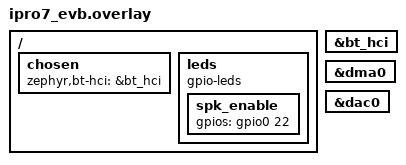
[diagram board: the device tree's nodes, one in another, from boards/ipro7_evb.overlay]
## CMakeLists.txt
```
# Copyright (c) 2026 INTELPRO
# SPDX-License-Identifier: Apache-2.0
#
# LE Audio unicast headset on the IPRO7AI EVK: CAP acceptor (CAS + CSIP set
# member), PACS/ASCS sink, VCP volume renderer; a phone's LE Audio unicast
# client (Android "LE Audio" headphones) streams LC3 over a CIS, decoded and
# played on the GPDAC speaker. Port of apps/bluetooth/le_audio/ipro_le_audio_headset.
cmake_minimum_required(VERSION 3.20.0)
find_package(Zephyr REQUIRED HINTS $ENV{ZEPHYR_BASE})
project(le_audio_headset_ipro)

target_include_directories(app PRIVATE ../common/audio)
target_sources(app PRIVATE src/main.c src/bap_server.c src/audio.c ../common/audio/pcm_out.c)
```

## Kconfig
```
# Copyright (c) 2026 INTELPRO
# SPDX-License-Identifier: Apache-2.0

mainmenu "Bluetooth: LE Audio unicast headset (IPRO7)"

config HEADSET_DEVICE_NAME
	string "Advertised device name"
	default "IPRO-LE-Audio"

config HEADSET_SINK_LOCATION
	int "PACS sink audio location bitmask (1 = front left, 2 = front right)"
	default 1

source "Kconfig.zephyr"
```

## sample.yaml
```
sample:
  name: LE Audio unicast headset (CAP acceptor, LC3 -> GPDAC speaker) on the IPRO7AI EVK
tests:
  sample.ipro.le_audio_headset:
    platform_allow:
      - ipro7ai_evk
    integration_platforms:
      - ipro7ai_evk
    tags:
      - ipro
      - bluetooth
      - leaudio
    build_only: true
```

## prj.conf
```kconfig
CONFIG_BT=y
CONFIG_LOG=y
CONFIG_LOG_MODE_MINIMAL=y
CONFIG_UTF8=y
CONFIG_BT_PERIPHERAL=y
CONFIG_BT_DEVICE_NAME="IPRO-LE-Audio"
CONFIG_BT_DEVICE_APPEARANCE=1089
CONFIG_BT_GAP_AUTO_UPDATE_CONN_PARAMS=n
CONFIG_BT_PERIPHERAL_PREF_MIN_INT=50
CONFIG_BT_PERIPHERAL_PREF_MAX_INT=70
CONFIG_BT_PERIPHERAL_PREF_LATENCY=0
CONFIG_BT_PERIPHERAL_PREF_TIMEOUT=400
CONFIG_BT_GATT_DYNAMIC_DB=y
CONFIG_BT_GATT_CLIENT=y
CONFIG_BT_SMP=y
CONFIG_BT_BONDABLE=y
CONFIG_BT_PRIVACY=y
CONFIG_BT_KEYS_OVERWRITE_OLDEST=y
CONFIG_BT_MAX_PAIRED=4
CONFIG_BT_SETTINGS=y
CONFIG_SETTINGS=y
CONFIG_SETTINGS_NVS=y
CONFIG_NVS=y
CONFIG_FLASH=y
CONFIG_FLASH_MAP=y
CONFIG_FLASH_PAGE_LAYOUT=y

# LE Audio: CAP acceptor, BAP unicast server (sink), VCP renderer
CONFIG_BT_AUDIO=y
CONFIG_BT_CAP_ACCEPTOR=y
CONFIG_BT_CAP_ACCEPTOR_SET_MEMBER=y
CONFIG_BT_CSIP_SET_MEMBER=y
CONFIG_BT_BAP_UNICAST_SERVER=y
CONFIG_BT_ATT_PREPARE_COUNT=1
CONFIG_BT_ASCS=y
CONFIG_BT_ASCS_MAX_ASE_SNK_COUNT=2
CONFIG_BT_ASCS_MAX_ASE_SRC_COUNT=0
CONFIG_BT_PAC_SNK=y
CONFIG_BT_PAC_SNK_LOC=y
CONFIG_BT_VCP_VOL_REND=y
CONFIG_BT_AUDIO_CODEC_CFG_MAX_METADATA_SIZE=24
CONFIG_BT_ISO_PERIPHERAL=y
CONFIG_BT_ISO_MAX_CHAN=2
CONFIG_BT_ISO_RX_BUF_COUNT=8
CONFIG_BT_ISO_RX_MTU=251
CONFIG_BT_BUF_ACL_RX_SIZE=255
CONFIG_BT_BUF_ACL_TX_SIZE=251
CONFIG_BT_L2CAP_TX_MTU=247

# LC3 decode (liblc3, FPU)
CONFIG_LIBLC3=y
CONFIG_FPU=y
CONFIG_MAIN_STACK_SIZE=8192
CONFIG_BT_RX_STACK_SIZE=4096
CONFIG_COMMON_LIBC_MALLOC_ARENA_SIZE=8192

# IPRO7 controller: CIS peripheral needs the ISO archive and 32 KB EM
CONFIG_IPRO7_EM_SIZE_KB=32
CONFIG_BT_IPRO_CTLR_LIB="link1_periph"
CONFIG_BT_IPRO_CTLR_FEATURE="bt54_iso2"
CONFIG_BT_MAX_CONN=1
CONFIG_ENTROPY_GENERATOR=y

# Speaker
CONFIG_DMA=y
CONFIG_DAC=y
CONFIG_DAC_IPRO_STREAM=y
CONFIG_GPIO=y
```

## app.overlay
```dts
/ {
	chosen {
		zephyr,bt-hci = &bt_hci;
	};
};

&bt_hci {
	status = "okay";
};

&dma0 {
	status = "okay";
};

&dac0 {
	status = "okay";
};
```

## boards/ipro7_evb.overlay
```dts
/ {
	chosen {
		zephyr,bt-hci = &bt_hci;
	};
};

&bt_hci {
	status = "okay";
};

&dma0 {
	status = "okay";
};

&dac0 {
	status = "okay";
};
/* Bench smoke on the EVB (no speaker): a spare pad stands in for the
 * class-D enable so the sample builds and the BLE side can be exercised. */
/ {
	leds {
		compatible = "gpio-leds";
		spk_enable: spk_enable {
			gpios = <&gpio0 22 GPIO_ACTIVE_HIGH>;
		};
	};
};
```

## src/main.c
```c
/*
 * Copyright (c) 2026 INTELPRO
 * SPDX-License-Identifier: Apache-2.0
 *
 * LE Audio unicast headset: advertises as a CAP acceptor (CAS + CSIP set
 * member of size 1, ASCS unicast announcement, Earbud appearance, RSI), lets
 * a phone connect, pair (bond kept in NVS) and stream LC3 to the speaker;
 * VCP volume renderer drives the output gain.
 */
#include <zephyr/kernel.h>
#include <zephyr/bluetooth/bluetooth.h>
#include <zephyr/bluetooth/conn.h>
#include <zephyr/bluetooth/gap.h>
#include <zephyr/bluetooth/uuid.h>
#include <zephyr/bluetooth/audio/audio.h>
#include <zephyr/bluetooth/audio/cap.h>
#include <zephyr/bluetooth/audio/csip.h>
#include <zephyr/bluetooth/audio/vcp.h>
#include <zephyr/settings/settings.h>
#include <zephyr/logging/log.h>
#include "audio.h"
#include "pcm_out.h"

LOG_MODULE_REGISTER(headset, CONFIG_LOG_DEFAULT_LEVEL);

int bap_server_init(void);

#define DEVICE_NAME     CONFIG_HEADSET_DEVICE_NAME
#define DEVICE_NAME_LEN (sizeof(DEVICE_NAME) - 1)

static const struct bt_data ad[] = {
	BT_DATA_BYTES(BT_DATA_FLAGS, (BT_LE_AD_GENERAL | BT_LE_AD_NO_BREDR)),
	BT_DATA(BT_DATA_NAME_COMPLETE, DEVICE_NAME, DEVICE_NAME_LEN),
	/* ASCS unicast announcement: general, no metadata */
	BT_DATA_BYTES(BT_DATA_SVC_DATA16, BT_UUID_16_ENCODE(BT_UUID_ASCS_VAL),
		      BT_AUDIO_UNICAST_ANNOUNCEMENT_GENERAL, 0x00),
};

/* Scan response: appearance, service list, and the CSIS RSI added at start. */
static const struct bt_data sd_static[] = {
	BT_DATA_BYTES(BT_DATA_GAP_APPEARANCE, BT_BYTES_LIST_LE16(CONFIG_BT_DEVICE_APPEARANCE)),
	BT_DATA_BYTES(BT_DATA_UUID16_ALL, BT_UUID_16_ENCODE(BT_UUID_CAS_VAL),
		      BT_UUID_16_ENCODE(BT_UUID_ASCS_VAL), BT_UUID_16_ENCODE(BT_UUID_PACS_VAL),
		      BT_UUID_16_ENCODE(BT_UUID_VCS_VAL)),
};

static struct bt_csip_set_member_svc_inst *csip_inst;
static uint8_t rsi[BT_CSIP_RSI_SIZE];
static struct bt_conn *current_conn;
static struct k_work_delayable adv_work;

static int advertising_start(void)
{
	struct bt_data sd[ARRAY_SIZE(sd_static) + 1];
	size_t sd_len = 0;
	int err;

	if (current_conn != NULL) {
		return 0;
	}
	for (size_t i = 0; i < ARRAY_SIZE(sd_static); i++) {
		sd[sd_len++] = sd_static[i];
	}
	if (csip_inst != NULL && bt_csip_set_member_generate_rsi(csip_inst, rsi) == 0) {
		sd[sd_len++] = (struct bt_data)BT_DATA(BT_DATA_CSIS_RSI, rsi, sizeof(rsi));
	}
	err = bt_le_adv_start(BT_LE_ADV_CONN_FAST_2, ad, ARRAY_SIZE(ad), sd, sd_len);
	if (err != 0 && err != -EALREADY) {
		LOG_ERR("advertising start: %d", err);
		return err;
	}
	LOG_INF("advertising as \"%s\"", DEVICE_NAME);
	return 0;
}

static void adv_work_fn(struct k_work *work)
{
	ARG_UNUSED(work);
	(void)advertising_start();
}

static void connected(struct bt_conn *conn, uint8_t err)
{
	char addr[BT_ADDR_LE_STR_LEN];

	bt_addr_le_to_str(bt_conn_get_dst(conn), addr, sizeof(addr));
	if (err != 0) {
		LOG_ERR("connection to %s failed (0x%02x)", addr, err);
		(void)k_work_reschedule(&adv_work, K_MSEC(500));
		return;
	}
	if (current_conn != NULL) {
		(void)bt_conn_disconnect(conn, BT_HCI_ERR_REMOTE_USER_TERM_CONN);
		return;
	}
	current_conn = bt_conn_ref(conn);
	LOG_INF("connected: %s", addr);
	err = bt_conn_set_security(conn, BT_SECURITY_L2);
	if (err != 0) {
		LOG_WRN("set security: %d", err);
	}
}

static void disconnected(struct bt_conn *conn, uint8_t reason)
{
	LOG_INF("disconnected (0x%02x)", reason);
	audio_stop();
	if (current_conn == conn) {
		bt_conn_unref(current_conn);
		current_conn = NULL;
	}
	(void)k_work_reschedule(&adv_work, K_MSEC(500));
}

static void security_changed(struct bt_conn *conn, bt_security_t level, enum bt_security_err err)
{
	ARG_UNUSED(conn);
	LOG_INF("security level %d (err %d)", level, err);
}

BT_CONN_CB_DEFINE(conn_cbs) = {
	.connected = connected,
	.disconnected = disconnected,
	.security_changed = security_changed,
};

static void pairing_complete(struct bt_conn *conn, bool bonded)
{
	ARG_UNUSED(conn);
	LOG_INF("pairing complete, bonded %d", bonded);
}

static void pairing_failed(struct bt_conn *conn, enum bt_security_err reason)
{
	ARG_UNUSED(conn);
	LOG_WRN("pairing failed: %d (forget the device on the phone and retry)", reason);
}

static struct bt_conn_auth_info_cb auth_info_cbs = {
	.pairing_complete = pairing_complete,
	.pairing_failed = pairing_failed,
};

/* ---- VCP volume renderer ------------------------------------------------ */

static void vcp_state(struct bt_conn *conn, int err, uint8_t volume, uint8_t mute)
{
	ARG_UNUSED(conn);
	if (err != 0) {
		return;
	}
	LOG_INF("volume %u mute %u", volume, mute);
	audio_set_volume(volume, mute != 0);
}

static void vcp_flags(struct bt_conn *conn, int err, uint8_t flags)
{
	ARG_UNUSED(conn); ARG_UNUSED(err); ARG_UNUSED(flags);
}

static struct bt_vcp_vol_rend_cb vcp_cbs = {.state = vcp_state, .flags = vcp_flags};

static int vcp_init(void)
{
	struct bt_vcp_vol_rend_register_param param = {
		.step = 16, .mute = BT_VCP_STATE_UNMUTED, .volume = 200, .cb = &vcp_cbs,
	};
	int err = bt_vcp_vol_rend_register(&param);

	if (err == 0) {
		audio_set_volume(param.volume, false);
	}
	return err;
}

/* ---- CAP acceptor (CAS + CSIP set member) -------------------------------- */

static int cap_init(void)
{
	static const uint8_t sirk[BT_CSIP_SIRK_SIZE] = {0x12, 0x34, 0x56, 0x78, 0x9a, 0xbc,
							 0xde, 0xf0, 0x11, 0x22, 0x33, 0x44,
							 0x55, 0x66, 0x77, 0x88};
	struct bt_csip_set_member_register_param csip = {
		.set_size = 1, .rank = 1, .lockable = true,
	};

	memcpy(csip.sirk, sirk, sizeof(sirk));
	return bt_cap_acceptor_register(&csip, &csip_inst);
}

int main(void)
{
	int err;

	LOG_INF("LE Audio unicast headset (IPRO7AI EVK)");
	err = bt_enable(NULL);
	if (err != 0) {
		LOG_ERR("bt_enable: %d", err);
		return 0;
	}
	if (IS_ENABLED(CONFIG_BT_SETTINGS)) {
		err = settings_load();
		LOG_INF("settings load: %d", err);
	}
	(void)bt_conn_auth_info_cb_register(&auth_info_cbs);
	err = cap_init();
	LOG_INF("CAP acceptor: %d", err);
	err = bap_server_init();
	if (err != 0) {
		return 0;
	}
	err = vcp_init();
	LOG_INF("VCP renderer: %d", err);
	(void)pcm_out_init();
	k_work_init_delayable(&adv_work, adv_work_fn);
	(void)advertising_start();
	return 0;
}

#ifdef CONFIG_SHELL
#include <zephyr/shell/shell.h>

static int cmd_hs_unpair(const struct shell *sh, size_t argc, char **argv)
{
	ARG_UNUSED(argc); ARG_UNUSED(argv);
	int err = bt_unpair(BT_ID_DEFAULT, NULL);

	shell_print(sh, "unpair all: %d", err);
	return 0;
}

static int cmd_hs_disconnect(const struct shell *sh, size_t argc, char **argv)
{
	ARG_UNUSED(argc); ARG_UNUSED(argv);
	if (current_conn == NULL) {
		shell_print(sh, "not connected");
		return 0;
	}
	shell_print(sh, "disconnect: %d",
		    bt_conn_disconnect(current_conn, BT_HCI_ERR_REMOTE_USER_TERM_CONN));
	return 0;
}

SHELL_STATIC_SUBCMD_SET_CREATE(sub_hs,
	SHELL_CMD(unpair, NULL, "forget all bonds", cmd_hs_unpair),
	SHELL_CMD(disconnect, NULL, "drop the current link", cmd_hs_disconnect),
	SHELL_SUBCMD_SET_END);
SHELL_CMD_REGISTER(hs, &sub_hs, "LE Audio headset", NULL);
#endif
```

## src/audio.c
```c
/*
 * Copyright (c) 2026 INTELPRO
 * SPDX-License-Identifier: Apache-2.0
 *
 * LC3 decode for the headset: SDUs from the CIS are queued (net_buf ref) to
 * a decoder thread so the Bluetooth RX thread never waits on the codec;
 * decoded mono PCM goes to pcm_out (GPDAC speaker). A lost or errored SDU
 * replays the last good frame (halving per consecutive loss) rather than
 * liblc3's sign-randomising PLC, which is a burst of noise on music.
 */
#include <zephyr/kernel.h>
#include <zephyr/logging/log.h>
#include <lc3.h>
#include <string.h>
#include "audio.h"
#include "pcm_out.h"

LOG_MODULE_REGISTER(headset_audio, CONFIG_LOG_DEFAULT_LEVEL);

#define MAX_FRAME_SAMPLES 480 /* 48 kHz x 10 ms */
#define QUEUE_DEPTH 8

struct sdu {
	void *fifo_reserved;
	struct net_buf *buf;
	uint8_t flags;
};

K_MEM_SLAB_DEFINE_STATIC(sdu_slab, sizeof(struct sdu), QUEUE_DEPTH, 4);
static K_FIFO_DEFINE(sdu_fifo);
static K_THREAD_STACK_DEFINE(dec_stack, 8192);
static struct k_thread dec_thread;

static struct {
	uint32_t rate, dur_us;
	uint16_t octets;
	lc3_decoder_t dec;
	lc3_decoder_mem_48k_t mem;
	int16_t pcm[MAX_FRAME_SAMPLES];
	int16_t last_good[MAX_FRAME_SAMPLES];
	int frame_samples;
	uint8_t lost_run;
	bool streaming;
	uint32_t rx, decoded, concealed, dropped, errors;
} a;

static void decode_one(struct sdu *s)
{
	const bool valid = (s->flags & BT_ISO_FLAGS_VALID) != 0 && s->buf != NULL &&
			   s->buf->len == a.octets;

	if (a.dec == NULL) {
		return;
	}
	if (valid) {
		int r = lc3_decode(a.dec, s->buf->data, a.octets, LC3_PCM_FORMAT_S16, a.pcm, 1);

		if (r < 0) {
			a.errors++;
			return;
		}
		memcpy(a.last_good, a.pcm, a.frame_samples * sizeof(int16_t));
		a.lost_run = 0;
		a.decoded++;
	} else {
		const int shift = MIN(a.lost_run, 8);

		for (int i = 0; i < a.frame_samples; i++) {
			a.pcm[i] = (int16_t)(a.last_good[i] >> shift);
		}
		if (a.lost_run < UINT8_MAX) {
			a.lost_run++;
		}
		a.concealed++;
	}
	(void)pcm_out_write(a.pcm, a.frame_samples);
	if ((++a.rx % 1000) == 0) {
		struct pcm_out_stats st;

		pcm_out_stats(&st);
		LOG_INF("%u SDUs: decoded %u, concealed %u, errors %u, dropped %u | ring %u B, underruns %u, overruns %u, step %d, peak in %d out %d",
			a.rx, a.decoded, a.concealed, a.errors, a.dropped, st.ring_bytes,
			st.underruns, st.overruns, st.step_q16, st.in_peak, st.out_peak);
	}
}

static void dec_thread_fn(void *p1, void *p2, void *p3)
{
	ARG_UNUSED(p1); ARG_UNUSED(p2); ARG_UNUSED(p3);
	while (true) {
		struct sdu *s = k_fifo_get(&sdu_fifo, K_FOREVER);

		if (a.streaming) {
			decode_one(s);
		}
		if (s->buf != NULL) {
			net_buf_unref(s->buf);
		}
		k_mem_slab_free(&sdu_slab, (void *)s);
	}
}

int audio_configure(uint32_t sample_rate, uint32_t frame_dur_us, uint16_t octets_per_frame)
{
	static bool thread_started;

	if (!thread_started) {
		k_thread_create(&dec_thread, dec_stack, K_THREAD_STACK_SIZEOF(dec_stack),
				dec_thread_fn, NULL, NULL, NULL, K_PRIO_PREEMPT(5), 0, K_NO_WAIT);
		k_thread_name_set(&dec_thread, "lc3_dec");
		thread_started = true;
	}
	if (a.streaming && (sample_rate != a.rate || frame_dur_us != a.dur_us)) {
		audio_stop();
	}
	a.rate = sample_rate;
	a.dur_us = frame_dur_us;
	a.octets = octets_per_frame;
	a.frame_samples = lc3_frame_samples((int)frame_dur_us, (int)sample_rate);
	if (a.frame_samples <= 0 || a.frame_samples > MAX_FRAME_SAMPLES) {
		LOG_ERR("unsupported LC3 config %u Hz / %u us", sample_rate, frame_dur_us);
		a.dec = NULL;
		return -ENOTSUP;
	}
	a.dec = lc3_setup_decoder((int)frame_dur_us, (int)sample_rate, 0, &a.mem);
	if (a.dec == NULL) {
		LOG_ERR("lc3_setup_decoder failed");
		return -EINVAL;
	}
	memset(a.last_good, 0, sizeof(a.last_good));
	a.lost_run = 0;
	LOG_INF("LC3 %u Hz, %u us, %u octets/frame (%d samples)", sample_rate, frame_dur_us,
		octets_per_frame, a.frame_samples);
	return 0;
}

int audio_start(void)
{
	int r;

	if (a.dec == NULL) {
		return -EINVAL;
	}
	if (a.streaming) {
		return 0;
	}
	r = pcm_out_start(a.rate);
	if (r != 0) {
		LOG_ERR("pcm_out_start: %d", r);
		return r;
	}
	a.rx = 0; a.decoded = 0; a.concealed = 0; a.dropped = 0; a.errors = 0;
	a.streaming = true;
	return 0;
}

void audio_stop(void)
{
	a.streaming = false;
	pcm_out_stop();
}

void audio_push(const struct bt_iso_recv_info *info, struct net_buf *buf)
{
	struct sdu *s;

	if (!a.streaming) {
		return;
	}
	if (k_mem_slab_alloc(&sdu_slab, (void **)&s, K_NO_WAIT) != 0) {
		a.dropped++;
		return;
	}
	s->buf = net_buf_ref(buf);
	s->flags = info != NULL ? info->flags : 0;
	k_fifo_put(&sdu_fifo, s);
}

void audio_set_volume(uint8_t volume, bool mute)
{
	pcm_out_set_volume(volume, mute);
}
```

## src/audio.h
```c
/*
 * Copyright (c) 2026 INTELPRO
 * SPDX-License-Identifier: Apache-2.0
 */
#ifndef HEADSET_AUDIO_H
#define HEADSET_AUDIO_H

#include <stdint.h>
#include <stdbool.h>
#include <zephyr/net_buf.h>
#include <zephyr/bluetooth/iso.h>

/* Codec configuration negotiated on the sink ASE. */
int audio_configure(uint32_t sample_rate, uint32_t frame_dur_us, uint16_t octets_per_frame);
/* Streaming state: opens/closes the speaker path. */
int audio_start(void);
void audio_stop(void);
/* One SDU from the CIS (any context); decoded on the audio thread. */
void audio_push(const struct bt_iso_recv_info *info, struct net_buf *buf);
void audio_set_volume(uint8_t volume, bool mute);

#endif
```

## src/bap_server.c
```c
/*
 * Copyright (c) 2026 INTELPRO
 * SPDX-License-Identifier: Apache-2.0
 *
 * BAP unicast server (sink): PACS capability, ASCS callbacks, stream ops.
 * Codec capability as the FreeRTOS headset: LC3 16/32/48 kHz, 7.5/10 ms,
 * 1 channel, 26..155 octets (48_6 at 124 kbps is the top mono set); a phone
 * usually picks 48_2 or 48_4 for media, 32_2/16_2 for calls.
 */
#include <zephyr/kernel.h>
#include <zephyr/bluetooth/bluetooth.h>
#include <zephyr/bluetooth/conn.h>
#include <zephyr/bluetooth/audio/audio.h>
#include <zephyr/bluetooth/audio/bap.h>
#include <zephyr/bluetooth/audio/pacs.h>
#include <zephyr/bluetooth/audio/lc3.h>
#include <zephyr/logging/log.h>
#include "audio.h"

LOG_MODULE_REGISTER(bap_server, CONFIG_LOG_DEFAULT_LEVEL);

static const struct bt_audio_codec_cap lc3_sink_codec_cap = BT_AUDIO_CODEC_CAP_LC3(
	BT_AUDIO_CODEC_CAP_FREQ_16KHZ | BT_AUDIO_CODEC_CAP_FREQ_32KHZ |
		BT_AUDIO_CODEC_CAP_FREQ_48KHZ,
	BT_AUDIO_CODEC_CAP_DURATION_7_5 | BT_AUDIO_CODEC_CAP_DURATION_10 |
		BT_AUDIO_CODEC_CAP_DURATION_PREFER_10,
	BT_AUDIO_CODEC_CAP_CHAN_COUNT_SUPPORT(1), 26, 155, 1,
	BT_AUDIO_CONTEXT_TYPE_MEDIA | BT_AUDIO_CONTEXT_TYPE_CONVERSATIONAL);

static struct bt_pacs_cap lc3_sink_cap = {.codec_cap = &lc3_sink_codec_cap};

static struct bt_bap_stream streams[CONFIG_BT_ASCS_MAX_ASE_SNK_COUNT];
static bool stream_used[CONFIG_BT_ASCS_MAX_ASE_SNK_COUNT];
static struct bt_bap_stream_ops stream_ops;
static uint32_t rx_sdus, rx_lost;

static void fill_qos_pref(struct bt_bap_qos_cfg_pref *pref)
{
	pref->unframed_supported = true;
	pref->phy = BT_BAP_QOS_CFG_2M;
	pref->rtn = 2;
	pref->latency = 10;
	pref->pd_min = 10000;
	pref->pd_max = 40000;
	pref->pref_pd_min = 10000;
	pref->pref_pd_max = 20000;
}

static struct bt_bap_stream *stream_alloc(void)
{
	for (size_t i = 0; i < ARRAY_SIZE(streams); i++) {
		if (!stream_used[i]) {
			stream_used[i] = true;
			return &streams[i];
		}
	}
	return NULL;
}

static void stream_free(struct bt_bap_stream *stream)
{
	for (size_t i = 0; i < ARRAY_SIZE(streams); i++) {
		if (&streams[i] == stream) {
			stream_used[i] = false;
		}
	}
}

static int apply_codec_cfg(const struct bt_audio_codec_cfg *codec_cfg)
{
	int freq = bt_audio_codec_cfg_get_freq(codec_cfg);
	int dur = bt_audio_codec_cfg_get_frame_dur(codec_cfg);
	int octets = bt_audio_codec_cfg_get_octets_per_frame(codec_cfg);

	if (freq < 0 || dur < 0 || octets <= 0) {
		LOG_WRN("codec config incomplete (freq %d dur %d octets %d)", freq, dur, octets);
		return -EINVAL;
	}
	return audio_configure(bt_audio_codec_cfg_freq_to_freq_hz(freq),
			       bt_audio_codec_cfg_frame_dur_to_frame_dur_us(dur), (uint16_t)octets);
}

static int cb_config(struct bt_conn *conn, const struct bt_bap_ep *ep, enum bt_audio_dir dir,
		     const struct bt_audio_codec_cfg *codec_cfg, struct bt_bap_stream **stream,
		     struct bt_bap_qos_cfg_pref *const pref, struct bt_bap_ascs_rsp *rsp)
{
	ARG_UNUSED(conn); ARG_UNUSED(ep);
	if (dir != BT_AUDIO_DIR_SINK) {
		*rsp = BT_BAP_ASCS_RSP(BT_BAP_ASCS_RSP_CODE_CONF_UNSUPPORTED,
				       BT_BAP_ASCS_REASON_NONE);
		return -ENOTSUP;
	}
	*stream = stream_alloc();
	if (*stream == NULL) {
		*rsp = BT_BAP_ASCS_RSP(BT_BAP_ASCS_RSP_CODE_NO_MEM, BT_BAP_ASCS_REASON_NONE);
		return -ENOMEM;
	}
	bt_bap_stream_cb_register(*stream, &stream_ops);
	LOG_INF("ASE config: stream %p", (void *)*stream);
	if (codec_cfg != NULL && apply_codec_cfg(codec_cfg) != 0) {
		stream_free(*stream);
		*stream = NULL;
		*rsp = BT_BAP_ASCS_RSP(BT_BAP_ASCS_RSP_CODE_CONF_UNSUPPORTED,
				       BT_BAP_ASCS_REASON_CODEC_DATA);
		return -ENOTSUP;
	}
	fill_qos_pref(pref);
	*rsp = BT_BAP_ASCS_RSP(BT_BAP_ASCS_RSP_CODE_SUCCESS, BT_BAP_ASCS_REASON_NONE);
	return 0;
}

static int cb_reconfig(struct bt_bap_stream *stream, enum bt_audio_dir dir,
		       const struct bt_audio_codec_cfg *codec_cfg,
		       struct bt_bap_qos_cfg_pref *const pref, struct bt_bap_ascs_rsp *rsp)
{
	ARG_UNUSED(dir);
	LOG_INF("ASE reconfig: stream %p", (void *)stream);
	if (codec_cfg != NULL) {
		(void)apply_codec_cfg(codec_cfg);
	}
	fill_qos_pref(pref);
	*rsp = BT_BAP_ASCS_RSP(BT_BAP_ASCS_RSP_CODE_SUCCESS, BT_BAP_ASCS_REASON_NONE);
	return 0;
}

static int cb_qos(struct bt_bap_stream *stream, const struct bt_bap_qos_cfg *qos,
		  struct bt_bap_ascs_rsp *rsp)
{
	LOG_INF("ASE QoS: stream %p interval %u framing %u phy %u sdu %u rtn %u latency %u pd %u",
		(void *)stream, qos->interval, qos->framing, qos->phy, qos->sdu, qos->rtn,
		qos->latency, qos->pd);
	*rsp = BT_BAP_ASCS_RSP(BT_BAP_ASCS_RSP_CODE_SUCCESS, BT_BAP_ASCS_REASON_NONE);
	return 0;
}

static int cb_enable(struct bt_bap_stream *stream, const uint8_t meta[], size_t meta_len,
		     struct bt_bap_ascs_rsp *rsp)
{
	ARG_UNUSED(meta); ARG_UNUSED(meta_len);
	LOG_INF("ASE enable: stream %p", (void *)stream);
	*rsp = BT_BAP_ASCS_RSP(BT_BAP_ASCS_RSP_CODE_SUCCESS, BT_BAP_ASCS_REASON_NONE);
	return 0;
}

static int cb_start(struct bt_bap_stream *stream, struct bt_bap_ascs_rsp *rsp)
{
	LOG_INF("ASE start: stream %p", (void *)stream);
	*rsp = BT_BAP_ASCS_RSP(BT_BAP_ASCS_RSP_CODE_SUCCESS, BT_BAP_ASCS_REASON_NONE);
	return 0;
}

static int cb_metadata(struct bt_bap_stream *stream, const uint8_t meta[], size_t meta_len,
		       struct bt_bap_ascs_rsp *rsp)
{
	ARG_UNUSED(meta);
	LOG_INF("ASE metadata: stream %p (%zu B)", (void *)stream, meta_len);
	*rsp = BT_BAP_ASCS_RSP(BT_BAP_ASCS_RSP_CODE_SUCCESS, BT_BAP_ASCS_REASON_NONE);
	return 0;
}

static int cb_disable(struct bt_bap_stream *stream, struct bt_bap_ascs_rsp *rsp)
{
	LOG_INF("ASE disable: stream %p", (void *)stream);
	*rsp = BT_BAP_ASCS_RSP(BT_BAP_ASCS_RSP_CODE_SUCCESS, BT_BAP_ASCS_REASON_NONE);
	return 0;
}

static int cb_stop(struct bt_bap_stream *stream, struct bt_bap_ascs_rsp *rsp)
{
	LOG_INF("ASE stop: stream %p", (void *)stream);
	*rsp = BT_BAP_ASCS_RSP(BT_BAP_ASCS_RSP_CODE_SUCCESS, BT_BAP_ASCS_REASON_NONE);
	return 0;
}

static int cb_release(struct bt_bap_stream *stream, struct bt_bap_ascs_rsp *rsp)
{
	LOG_INF("ASE release: stream %p", (void *)stream);
	*rsp = BT_BAP_ASCS_RSP(BT_BAP_ASCS_RSP_CODE_SUCCESS, BT_BAP_ASCS_REASON_NONE);
	return 0;
}

static const struct bt_bap_unicast_server_cb unicast_server_cb = {
	.config = cb_config, .reconfig = cb_reconfig, .qos = cb_qos, .enable = cb_enable,
	.start = cb_start, .metadata = cb_metadata, .disable = cb_disable, .stop = cb_stop,
	.release = cb_release,
};

/* ---- stream ops ------------------------------------------------------- */

static void stream_enabled(struct bt_bap_stream *stream)
{
	/* Sink ASE: tell the client the receiver is ready so the ASE moves to
	 * Streaming once the CIS is up. */
	int err = bt_bap_stream_start(stream);

	LOG_INF("stream %p enabled, receiver start: %d", (void *)stream, err);
}

static void stream_started(struct bt_bap_stream *stream)
{
	LOG_INF("stream %p started", (void *)stream);
	rx_sdus = 0; rx_lost = 0;
	(void)audio_start();
}

static void stream_stopped(struct bt_bap_stream *stream, uint8_t reason)
{
	LOG_INF("stream %p stopped (0x%02x), %u SDUs, %u lost", (void *)stream, reason, rx_sdus,
		rx_lost);
	audio_stop();
}

static void stream_released(struct bt_bap_stream *stream)
{
	LOG_INF("stream %p released", (void *)stream);
	audio_stop();
	stream_free(stream);
}

static void stream_recv(struct bt_bap_stream *stream, const struct bt_iso_recv_info *info,
			struct net_buf *buf)
{
	ARG_UNUSED(stream);
	rx_sdus++;
	if ((info->flags & BT_ISO_FLAGS_VALID) == 0) {
		rx_lost++;
	}
	audio_push(info, buf);
}

static struct bt_bap_stream_ops stream_ops = {
	.enabled = stream_enabled,
	.started = stream_started,
	.stopped = stream_stopped,
	.released = stream_released,
	.recv = stream_recv,
};

int bap_server_init(void)
{
	struct bt_pacs_register_param pacs_param = {.snk_pac = true, .snk_loc = true};
	struct bt_bap_unicast_server_register_param server_param = {
		.snk_cnt = CONFIG_BT_ASCS_MAX_ASE_SNK_COUNT,
		.src_cnt = CONFIG_BT_ASCS_MAX_ASE_SRC_COUNT,
	};
	int err;

	err = bt_pacs_register(&pacs_param);
	if (err != 0 && err != -EALREADY) {
		LOG_ERR("PACS register: %d", err);
		return err;
	}
	err = bt_pacs_cap_register(BT_AUDIO_DIR_SINK, &lc3_sink_cap);
	if (err != 0) {
		LOG_ERR("PACS sink cap: %d", err);
		return err;
	}
	err = bt_pacs_set_location(BT_AUDIO_DIR_SINK, CONFIG_HEADSET_SINK_LOCATION);
	if (err != 0) {
		LOG_ERR("PACS sink location: %d", err);
		return err;
	}
	(void)bt_pacs_set_supported_contexts(BT_AUDIO_DIR_SINK,
					     BT_AUDIO_CONTEXT_TYPE_MEDIA |
						     BT_AUDIO_CONTEXT_TYPE_CONVERSATIONAL |
						     BT_AUDIO_CONTEXT_TYPE_UNSPECIFIED);
	(void)bt_pacs_set_available_contexts(BT_AUDIO_DIR_SINK,
					     BT_AUDIO_CONTEXT_TYPE_MEDIA |
						     BT_AUDIO_CONTEXT_TYPE_CONVERSATIONAL |
						     BT_AUDIO_CONTEXT_TYPE_UNSPECIFIED);
	err = bt_bap_unicast_server_register(&server_param);
	if (err != 0 && err != -EALREADY) {
		LOG_ERR("ASCS register: %d", err);
		return err;
	}
	err = bt_bap_unicast_server_register_cb(&unicast_server_cb);
	if (err != 0) {
		LOG_ERR("BAP callbacks: %d", err);
		return err;
	}
	LOG_INF("BAP unicast server ready (%u sink ASE)", CONFIG_BT_ASCS_MAX_ASE_SNK_COUNT);
	return 0;
}
```
